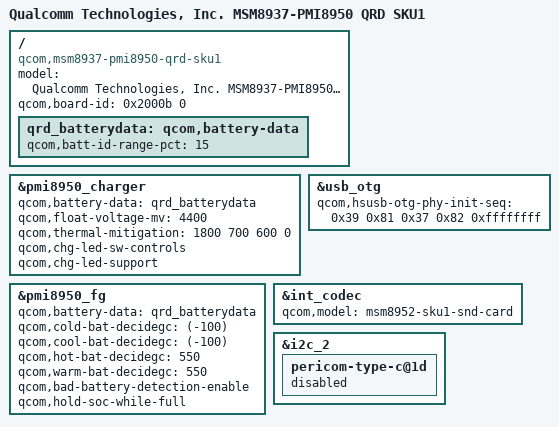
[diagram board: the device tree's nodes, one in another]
/*
 * Copyright (c) 2015-2016, The Linux Foundation. All rights reserved.
 *
 * This program is free software; you can redistribute it and/or modify
 * it under the terms of the GNU General Public License version 2 and
 * only version 2 as published by the Free Software Foundation.
 *
 * This program is distributed in the hope that it will be useful,
 * but WITHOUT ANY WARRANTY; without even the implied warranty of
 * MERCHANTABILITY or FITNESS FOR A PARTICULAR PURPOSE.  See the
 * GNU General Public License for more details.
 */

/dts-v1/;

#include "msm8937.dtsi"
#include "msm8937-pmi8950-qrd-sku1.dtsi"

/ {
	model = "Qualcomm Technologies, Inc. MSM8937-PMI8950 QRD SKU1";
	compatible = "qcom,msm8937-pmi8950-qrd-sku1",
		   "qcom,msm8937-qrd", "qcom,msm8937", "qcom,qrd";
	qcom,board-id= <0x2000b 0>;
};

/ {
	qrd_batterydata: qcom,battery-data {
		qcom,batt-id-range-pct = <15>;
		#include "batterydata-qrd-sku1-4v4-2800mah.dtsi"
	};
};

&pmi8950_charger {
	qcom,battery-data = <&qrd_batterydata>;
	qcom,float-voltage-mv = <4400>;
	/*
	 * The battery profile allows up to 2600 mA fast charge current.
	 * Keep the deeper thermal protection levels intact, but raise the
	 * first mitigation ceiling from the PMI8950 common default of
	 * 1500 mA to 1800 mA for this GM8/MSM8937 SKU only.
	 */
	qcom,thermal-mitigation = <1800 700 600 0>;
	qcom,chg-led-sw-controls;
	qcom,chg-led-support;
	status = "okay";
};

&usb_otg {
	qcom,hsusb-otg-phy-init-seq =
		<0x39 0x81 0x37 0x82 0xffffffff>;
};

&pmi8950_fg {
	qcom,battery-data = <&qrd_batterydata>;
	qcom,cold-bat-decidegc = <(-100)>;
	qcom,cool-bat-decidegc = <(-100)>;
	qcom,hot-bat-decidegc = <550>;
	qcom,warm-bat-decidegc = <550>;
	qcom,bad-battery-detection-enable;
	qcom,hold-soc-while-full;
};

&int_codec {
	qcom,model = "msm8952-sku1-snd-card";
};

&i2c_2 {
	pericom-type-c@1d {
		status="disabled";
	};
};
